AUTOSAR XML (schema 4-2-2)
package /STELLANTIS/EPT/ASWCs
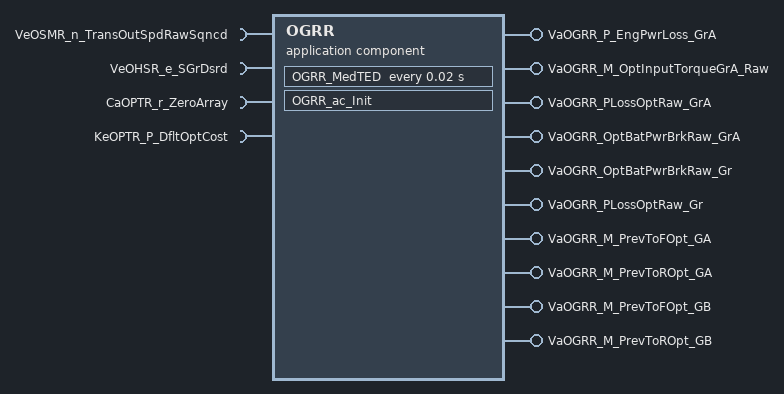
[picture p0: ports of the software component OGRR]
  application sw component type OGRR
    require port VeOSMR_n_TransOutSpdRawSqncd: nonqueued-receiver-com-spec{data-element=Value, init-value=0}, required-interface=VeOSMR_n_TransOutSpdRawSqncd
    require port VeOHSR_e_SGrDsrd: nonqueued-receiver-com-spec{data-element=Value, init-value=CeOHSR_e_SG_Reverse}, required-interface=VeOHSR_e_SGrDsrd
    10 x provide port, all with nonqueued-sender-com-spec{data-element=Value, init-value=9 x 0}:
      VaOGRR_P_EngPwrLoss_GrA: provided-interface=VaOGRR_P_EngPwrLoss_GrA
      VaOGRR_M_OptInputTorqueGrA_Raw: provided-interface=VaOGRR_M_OptInputTorqueGrA_Raw
      VaOGRR_PLossOptRaw_GrA: provided-interface=VaOGRR_PLossOptRaw_GrA
      VaOGRR_OptBatPwrBrkRaw_GrA: provided-interface=VaOGRR_OptBatPwrBrkRaw_GrA
      VaOGRR_OptBatPwrBrkRaw_Gr: provided-interface=VaOGRR_OptBatPwrBrkRaw_Gr
      VaOGRR_PLossOptRaw_Gr: provided-interface=VaOGRR_PLossOptRaw_Gr
      VaOGRR_M_PrevToFOpt_GA: provided-interface=VaOGRR_M_PrevToFOpt_GA
      VaOGRR_M_PrevToROpt_GA: provided-interface=VaOGRR_M_PrevToROpt_GA
      VaOGRR_M_PrevToFOpt_GB: provided-interface=VaOGRR_M_PrevToFOpt_GB
      VaOGRR_M_PrevToROpt_GB: provided-interface=VaOGRR_M_PrevToROpt_GB
    require port CaOPTR_r_ZeroArray: parameter-require-com-spec{init-value=CaOPTR_r_ZeroArray_CaOPTR_r_ZeroArray:[CaOPTR_r_ZeroArray_CaOPTR_r_ZeroArray_rt_Array_Float_9_1:0, CaOPTR_r_ZeroArray_CaOPTR_r_ZeroArray_rt_Array_Float_9_2:0, CaOPTR_r_ZeroArray_CaOPTR_r_ZeroArray_rt_Array_Float_9_3:0, CaOPTR_r_ZeroArray_CaOPTR_r_ZeroArray_rt_Array_Float_9_4:0, CaOPTR_r_ZeroArray_CaOPTR_r_ZeroArray_rt_Array_Float_9_5:0, CaOPTR_r_ZeroArray_CaOPTR_r_ZeroArray_rt_Array_Float_9_6:0, CaOPTR_r_ZeroArray_CaOPTR_r_ZeroArray_rt_Array_Float_9_7:0, CaOPTR_r_ZeroArray_CaOPTR_r_ZeroArray_rt_Array_Float_9_8:0, CaOPTR_r_ZeroArray_CaOPTR_r_ZeroArray_rt_Array_Float_9_9:0], parameter=CaOPTR_r_ZeroArray}, required-interface=CaOPTR_r_ZeroArray
    require port KeOPTR_P_DfltOptCost: parameter-require-com-spec{init-value=KeOPTR_P_DfltOptCost_KeOPTR_P_DfltOptCost:1000000, parameter=KeOPTR_P_DfltOptCost}, required-interface=KeOPTR_P_DfltOptCost
    behavior IB_OGRR: data-type-mapping=msADTtoIDTMapping, handle-termination-and-restart=NO-SUPPORT, included-data-type-set=data-type=TeTSXR_e_PrfrdComb
      timing event Event_MedTED: start-on-event=OGRR_MedTED, period=0.02
      init event Event_OGRR_ac_Init: start-on-event=OGRR_ac_Init
      runnable OGRR_ac_Init
        data-send-points:
          10 x access:
            OUT_VaOGRR_OptBatPwrBrkRaw_GrA_Value: accessed-variable=VaOGRR_OptBatPwrBrkRaw_GrA.Value
            OUT_VaOGRR_OptBatPwrBrkRaw_Gr_Value: accessed-variable=VaOGRR_OptBatPwrBrkRaw_Gr.Value
            OUT_VaOGRR_P_EngPwrLoss_GrA_Value: accessed-variable=VaOGRR_P_EngPwrLoss_GrA.Value
            OUT_VaOGRR_M_OptInputTorqueGrA_Raw_Value: accessed-variable=VaOGRR_M_OptInputTorqueGrA_Raw.Value
            OUT_VaOGRR_PLossOptRaw_Gr_Value: accessed-variable=VaOGRR_PLossOptRaw_Gr.Value
            OUT_VaOGRR_PLossOptRaw_GrA_Value: accessed-variable=VaOGRR_PLossOptRaw_GrA.Value
            OUT_VaOGRR_M_PrevToFOpt_GA_Value: accessed-variable=VaOGRR_M_PrevToFOpt_GA.Value
            OUT_VaOGRR_M_PrevToROpt_GA_Value: accessed-variable=VaOGRR_M_PrevToROpt_GA.Value
            OUT_VaOGRR_M_PrevToFOpt_GB_Value: accessed-variable=VaOGRR_M_PrevToFOpt_GB.Value
            OUT_VaOGRR_M_PrevToROpt_GB_Value: accessed-variable=VaOGRR_M_PrevToROpt_GB.Value
        parameter access CALPRM_CaOPTR_r_ZeroArray_CaOPTR_r_ZeroArray: accessed-parameter=CaOPTR_r_ZeroArray.CaOPTR_r_ZeroArray
        parameter access CALPRM_KeOPTR_P_DfltOptCost_KeOPTR_P_DfltOptCost: accessed-parameter=KeOPTR_P_DfltOptCost.KeOPTR_P_DfltOptCost
      runnable OGRR_MedTED
        data-send-points:
          10 x access:
            OUT_VaOGRR_P_EngPwrLoss_GrA_Value: accessed-variable=VaOGRR_P_EngPwrLoss_GrA.Value
            OUT_VaOGRR_M_OptInputTorqueGrA_Raw_Value: accessed-variable=VaOGRR_M_OptInputTorqueGrA_Raw.Value
            OUT_VaOGRR_PLossOptRaw_GrA_Value: accessed-variable=VaOGRR_PLossOptRaw_GrA.Value
            OUT_VaOGRR_PLossOptRaw_Gr_Value: accessed-variable=VaOGRR_PLossOptRaw_Gr.Value
            OUT_VaOGRR_OptBatPwrBrkRaw_GrA_Value: accessed-variable=VaOGRR_OptBatPwrBrkRaw_GrA.Value
            OUT_VaOGRR_OptBatPwrBrkRaw_Gr_Value: accessed-variable=VaOGRR_OptBatPwrBrkRaw_Gr.Value
            OUT_VaOGRR_M_PrevToFOpt_GA_Value: accessed-variable=VaOGRR_M_PrevToFOpt_GA.Value
            OUT_VaOGRR_M_PrevToROpt_GA_Value: accessed-variable=VaOGRR_M_PrevToROpt_GA.Value
            OUT_VaOGRR_M_PrevToFOpt_GB_Value: accessed-variable=VaOGRR_M_PrevToFOpt_GB.Value
            OUT_VaOGRR_M_PrevToROpt_GB_Value: accessed-variable=VaOGRR_M_PrevToROpt_GB.Value
        parameter access CALPRM_CaOPTR_r_ZeroArray_CaOPTR_r_ZeroArray: accessed-parameter=CaOPTR_r_ZeroArray.CaOPTR_r_ZeroArray
        parameter access CALPRM_KeOPTR_P_DfltOptCost_KeOPTR_P_DfltOptCost: accessed-parameter=KeOPTR_P_DfltOptCost.KeOPTR_P_DfltOptCost
      13 x variation point proxy, all with category=CONDITION:
        Variant_HSCL_3Mot_Enbl: condition-access=0
        Variant_OGRR_EnblG: condition-access=0
        Variant_OPTR_Enbl3MtrSys: condition-access=0
        Variant_OPTR_EnblGrA: condition-access=0
        Variant_OPTR_EnblWEDRsrv: condition-access=1
        Variant_OPTR_OptBatPwrBrkEnbl: condition-access=1
        Variant_SCOR_MtrxSelP1P2p5: condition-access=0
        Variant_TSXR_MtrALimToFSel: condition-access=1
        Variant_TSXR_MtrALimToRSel: condition-access=0
        Variant_TSXR_MtrBLimToFSel: condition-access=0
        Variant_TSXR_MtrBLimToRSel: condition-access=1
        Variant_TSXR_MtrCLimToFSel: condition-access=0
        Variant_TSXR_MtrCLimToRSel: condition-access=0
